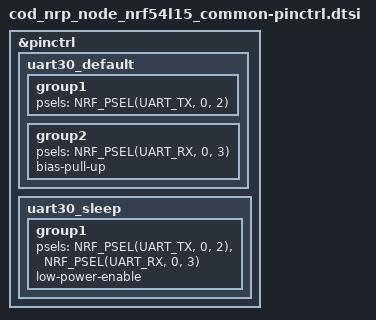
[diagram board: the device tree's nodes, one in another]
/*
 * Copyright (c) 2025 Codium Electronique
 * All rights reserved.
 */

&pinctrl {
	/* UART20 used as LPUART HCI interface with 9151 host
	 * FIXME: adapt pins */
	/*/omit-if-no-ref/
	uart20_default: uart20_default {
		group1 {
			psels = <NRF_PSEL(UART_TX, 1, 6)>;
		};

		group2 {
			psels = <NRF_PSEL(UART_RX, 1, 7)>;
			bias-pull-up;
		};
	};

	/omit-if-no-ref/
	uart20_sleep: uart20_sleep {
		group1 {
			psels = <NRF_PSEL(UART_RX, 1, 7)>;
			low-power-enable;
		};

		group2 {
			psels = <NRF_PSEL(UART_TX, 1, 6)>;
			low-power-enable;
			bias-pull-up;
		};
	};*/

	/* b0, mcuboot and TF-M logs
	 * NOTE: P0.00 and P0.01 are used on rev A, so we take P0.02 and P0.03
	 * which are also available on rev A */
	/omit-if-no-ref/
	uart30_default: uart30_default {
		group1 {
			psels = <NRF_PSEL(UART_TX, 0, 2)>;
		};

		group2 {
			psels = <NRF_PSEL(UART_RX, 0, 3)>;
			bias-pull-up;
		};
	};

	/omit-if-no-ref/
	uart30_sleep: uart30_sleep {
		group1 {
			psels = <NRF_PSEL(UART_TX, 0, 2)>,
				<NRF_PSEL(UART_RX, 0, 3)>;
			low-power-enable;
		};
	};
};
